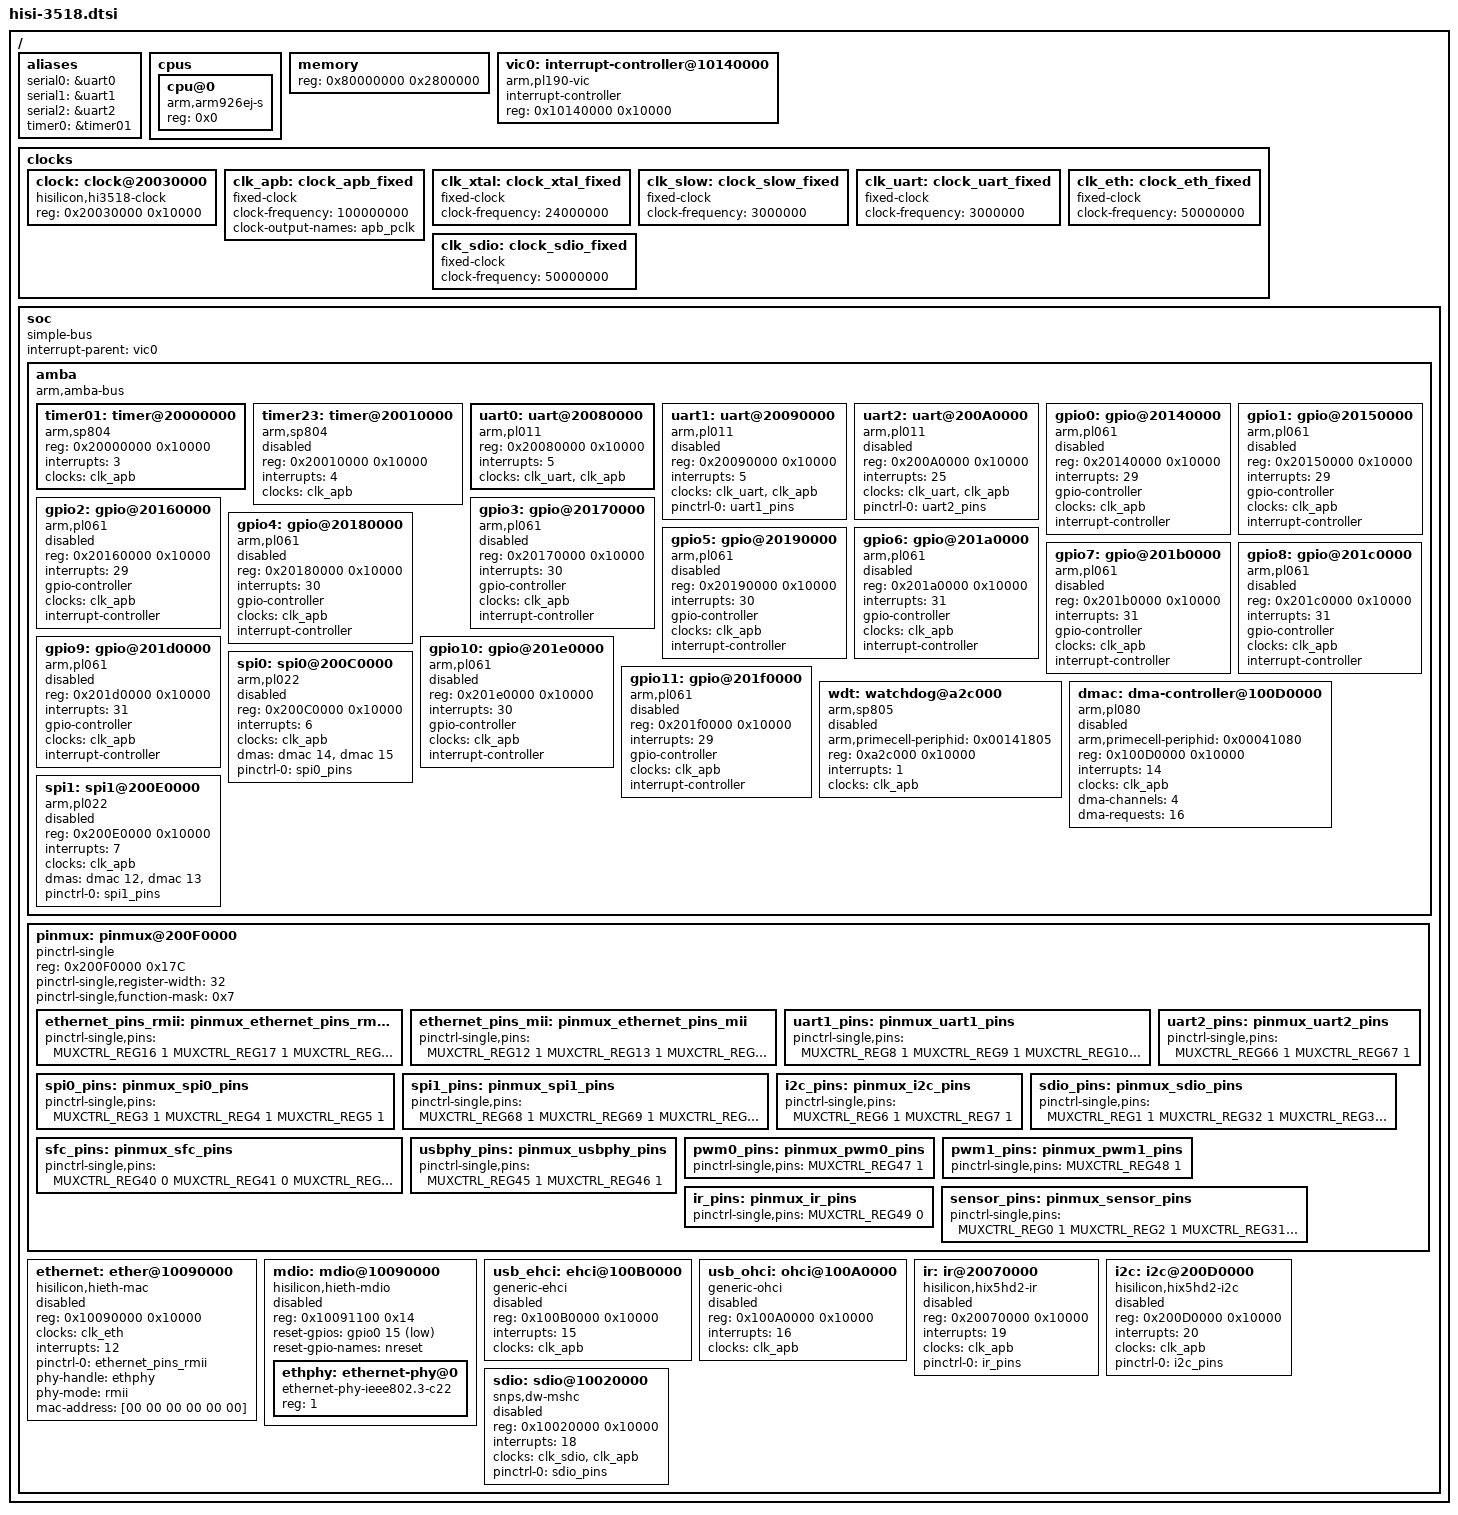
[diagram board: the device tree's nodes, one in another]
/*
 * Copyright (c) 2015 Robert Lukierski.
 * Copyright (c) 2013-2014 Linaro Ltd.
 * Copyright (c) 2013-2014 Hisilicon Limited.
 *
 * This program is free software; you can redistribute it and/or modify
 * it under the terms of the GNU General Public License version 2 as
 * publishhed by the Free Software Foundation.
 */

#include "skeleton.dtsi"
#include <dt-bindings/gpio/gpio.h>
#include <dt-bindings/input/input.h>
#include <dt-bindings/interrupt-controller/irq.h>
#include <dt-bindings/clock/hi3518-clock.h>

#define MUXCTRL_REG0 0x000
#define MUXCTRL_REG1 0x004
#define MUXCTRL_REG2 0x008
#define MUXCTRL_REG3 0x00C
#define MUXCTRL_REG4 0x010
#define MUXCTRL_REG5 0x014
#define MUXCTRL_REG6 0x018
#define MUXCTRL_REG7 0x01C
#define MUXCTRL_REG8 0x020
#define MUXCTRL_REG9 0x024
#define MUXCTRL_REG10 0x028
#define MUXCTRL_REG11 0x02C
#define MUXCTRL_REG12 0x030
#define MUXCTRL_REG13 0x034
#define MUXCTRL_REG14 0x038
#define MUXCTRL_REG15 0x03C
#define MUXCTRL_REG16 0x040
#define MUXCTRL_REG17 0x044
#define MUXCTRL_REG18 0x048
#define MUXCTRL_REG19 0x04C
#define MUXCTRL_REG20 0x050
#define MUXCTRL_REG21 0x054
#define MUXCTRL_REG22 0x058
#define MUXCTRL_REG23 0x05C
#define MUXCTRL_REG24 0x060
#define MUXCTRL_REG25 0x064
#define MUXCTRL_REG26 0x068
#define MUXCTRL_REG27 0x06C
#define MUXCTRL_REG28 0x070
#define MUXCTRL_REG29 0x074
#define MUXCTRL_REG30 0x078
#define MUXCTRL_REG31 0x07C
#define MUXCTRL_REG32 0x080
#define MUXCTRL_REG33 0x084
#define MUXCTRL_REG34 0x088
#define MUXCTRL_REG35 0x08C
#define MUXCTRL_REG36 0x090
#define MUXCTRL_REG37 0x094
#define MUXCTRL_REG38 0x098
#define MUXCTRL_REG39 0x09C
#define MUXCTRL_REG40 0x0A0
#define MUXCTRL_REG41 0x0A4
#define MUXCTRL_REG42 0x0A8
#define MUXCTRL_REG43 0x0AC
#define MUXCTRL_REG44 0x0B0
#define MUXCTRL_REG45 0x0B4
#define MUXCTRL_REG46 0x0B8
#define MUXCTRL_REG47 0x0BC
#define MUXCTRL_REG48 0x0C0
#define MUXCTRL_REG49 0x0C4
#define MUXCTRL_REG50 0x0C8
#define MUXCTRL_REG51 0x0CC
#define MUXCTRL_REG52 0x0D0
#define MUXCTRL_REG53 0x0D4
#define MUXCTRL_REG54 0x0D8
#define MUXCTRL_REG55 0x0DC
#define MUXCTRL_REG56 0x0E0
#define MUXCTRL_REG57 0x0E4
#define MUXCTRL_REG58 0x0E8
#define MUXCTRL_REG59 0x0EC
#define MUXCTRL_REG60 0x0F0
#define MUXCTRL_REG61 0x0F4
#define MUXCTRL_REG62 0x0F8
#define MUXCTRL_REG63 0x0FC
#define MUXCTRL_REG64 0x100
#define MUXCTRL_REG65 0x104
#define MUXCTRL_REG66 0x108
#define MUXCTRL_REG67 0x10C
#define MUXCTRL_REG68 0x110
#define MUXCTRL_REG69 0x114
#define MUXCTRL_REG70 0x118
#define MUXCTRL_REG71 0x11C
#define MUXCTRL_REG72 0x120
#define MUXCTRL_REG73 0x124
#define MUXCTRL_REG74 0x128
#define MUXCTRL_REG75 0x12C
#define MUXCTRL_REG76 0x130
#define MUXCTRL_REG77 0x134
#define MUXCTRL_REG78 0x138
#define MUXCTRL_REG79 0x13C
#define MUXCTRL_REG80 0x140
#define MUXCTRL_REG81 0x144
#define MUXCTRL_REG82 0x148
#define MUXCTRL_REG83 0x14C
#define MUXCTRL_REG84 0x150
#define MUXCTRL_REG85 0x154
#define MUXCTRL_REG86 0x158
#define MUXCTRL_REG87 0x15C
#define MUXCTRL_REG88 0x160
#define MUXCTRL_REG89 0x164
#define MUXCTRL_REG90 0x168
#define MUXCTRL_REG91 0x16C
#define MUXCTRL_REG92 0x170
#define MUXCTRL_REG93 0x174
#define MUXCTRL_REG94 0x178

/ {
    aliases {
        serial0 = &uart0;
        serial1 = &uart1;
        serial2 = &uart2;
        timer0 = &timer01;
    };
    
    cpus {
        #size-cells = <0>;
        #address-cells = <1>;
        
        cpu@0 {
            device_type = "cpu";
            compatible = "arm,arm926ej-s";
            reg = <0x0>;
        };
    };
    
    memory {
        device_type = "memory";
        reg = <0x80000000 0x2800000>; // 40 MB
    };
    
    vic0: interrupt-controller@10140000 {
        compatible = "arm,pl190-vic";
        interrupt-controller;
        #interrupt-cells = <1>;
        reg = <0x10140000 0x10000>;
        status = "okay";
    };
    
    clocks {
        #address-cells = <1>;
        #size-cells = <1>;
        ranges;
        
        clock: clock@20030000 {
            compatible = "hisilicon,hi3518-clock";
            reg = <0x20030000 0x10000>;
            #clock-cells = <1>;
        };
        
        clk_apb: clock_apb_fixed {
            compatible = "fixed-clock";
            #clock-cells = <0>;
            clock-frequency = <100000000>; 
            clock-output-names = "apb_pclk";
        };
        
        clk_xtal: clock_xtal_fixed {
            #clock-cells = <0>;
            compatible = "fixed-clock";
            clock-frequency = <24000000>;
        };
        
        clk_slow: clock_slow_fixed {
            #clock-cells = <0>;
            compatible = "fixed-clock";
            clock-frequency = <3000000>;
        };
        
        clk_uart: clock_uart_fixed {
            #clock-cells = <0>;
            compatible = "fixed-clock";
            clock-frequency = <3000000>;
        };
        
        clk_eth: clock_eth_fixed {
            #clock-cells = <0>;
            compatible = "fixed-clock";
            clock-frequency = <50000000>;
        };
        
        clk_sdio: clock_sdio_fixed {
            #clock-cells = <0>;
            compatible = "fixed-clock";
            clock-frequency = <50000000>;
        };
    };

    soc {
        device_type = "soc";
        #address-cells = <1>;
        #size-cells = <1>;
        compatible = "simple-bus";
        interrupt-parent = <&vic0>;
        ranges;

        amba {
            #address-cells = <1>;
            #size-cells = <1>;
            compatible = "arm,amba-bus";
            ranges;

            timer01: timer@20000000 {
                compatible = "arm,sp804", "arm,primecell";
                reg = <0x20000000 0x10000>;
                interrupts = <3>;
                clocks = <&clk_apb>;
                clock-names = "apb_pclk";
                status = "okay";
            };

            timer23: timer@20010000 {
                compatible = "arm,sp804", "arm,primecell";
                reg = <0x20010000 0x10000>;
                interrupts = <4>;
                clocks = <&clk_apb>;
                clock-names = "apb_pclk";
                status = "disabled";
            };
            
            uart0: uart@20080000 {
                compatible = "arm,pl011", "arm,primecell";
                reg = <0x20080000 0x10000>;
                interrupts = <5>;
                clocks = <&clk_uart>, <&clk_apb>;
                clock-names = "uartclk", "apb_pclk";
                status = "okay";
            };

            uart1: uart@20090000 {
                compatible = "arm,pl011", "arm,primecell";
                reg = <0x20090000 0x10000>;
                interrupts = <5>;
                clocks = <&clk_uart>, <&clk_apb>;
                clock-names = "uartclk", "apb_pclk";
                pinctrl-names = "default";
                pinctrl-0 = <&uart1_pins>;
                status = "disabled";
            };

            uart2: uart@200A0000 {
                compatible = "arm,pl011", "arm,primecell";
                reg = <0x200A0000 0x10000>;
                interrupts = <25>;
                clocks = <&clk_uart>, <&clk_apb>;
                clock-names = "uartclk", "apb_pclk";
                pinctrl-names = "default";
                pinctrl-0 = <&uart2_pins>;
                status = "disabled";
            };

            gpio0: gpio@20140000 {
                compatible = "arm,pl061", "arm,primecell";
                reg = <0x20140000 0x10000>;
                interrupts = <29>;
                gpio-controller;
                #gpio-cells = <2>;
                clocks = <&clk_apb>;
                clock-names = "apb_pclk";
                interrupt-controller;
                #interrupt-cells = <2>;
                status = "disabled";
            };

            gpio1: gpio@20150000 {
                compatible = "arm,pl061", "arm,primecell";
                reg = <0x20150000 0x10000>;
                interrupts = <29>;
                gpio-controller;
                #gpio-cells = <2>;
                clocks = <&clk_apb>;
                clock-names = "apb_pclk";
                interrupt-controller;
                #interrupt-cells = <2>;
                status = "disabled";
            };

            gpio2: gpio@20160000 {
                compatible = "arm,pl061", "arm,primecell";
                reg = <0x20160000 0x10000>;
                interrupts = <29>;
                gpio-controller;
                #gpio-cells = <2>;
                clocks = <&clk_apb>;
                clock-names = "apb_pclk";
                interrupt-controller;
                #interrupt-cells = <2>;
                status = "disabled";
            };

            gpio3: gpio@20170000 {
                compatible = "arm,pl061", "arm,primecell";
                reg = <0x20170000 0x10000>;
                interrupts = <30>;
                gpio-controller;
                #gpio-cells = <2>;
                clocks = <&clk_apb>;
                clock-names = "apb_pclk";
                interrupt-controller;
                #interrupt-cells = <2>;
                status = "disabled";
            };

            gpio4: gpio@20180000 {
                compatible = "arm,pl061", "arm,primecell";
                reg = <0x20180000 0x10000>;
                interrupts = <30>;
                gpio-controller;
                #gpio-cells = <2>;
                clocks = <&clk_apb>;
                clock-names = "apb_pclk";
                interrupt-controller;
                #interrupt-cells = <2>;
                status = "disabled";
            };

            gpio5: gpio@20190000 {
                compatible = "arm,pl061", "arm,primecell";
                reg = <0x20190000 0x10000>;
                interrupts = <30>;
                gpio-controller;
                #gpio-cells = <2>;
                clocks = <&clk_apb>;
                clock-names = "apb_pclk";
                interrupt-controller;
                #interrupt-cells = <2>;
                status = "disabled";
            };

            gpio6: gpio@201a0000 {
                compatible = "arm,pl061", "arm,primecell";
                reg = <0x201a0000 0x10000>;
                interrupts = <31>;
                gpio-controller;
                #gpio-cells = <2>;
                clocks = <&clk_apb>;
                clock-names = "apb_pclk";
                interrupt-controller;
                #interrupt-cells = <2>;
                status = "disabled";
            };

            gpio7: gpio@201b0000 {
                compatible = "arm,pl061", "arm,primecell";
                reg = <0x201b0000 0x10000>;
                interrupts = <31>;
                gpio-controller;
                #gpio-cells = <2>;
                clocks = <&clk_apb>;
                clock-names = "apb_pclk";
                interrupt-controller;
                #interrupt-cells = <2>;
                status = "disabled";
            };

            gpio8: gpio@201c0000 {
                compatible = "arm,pl061", "arm,primecell";
                reg = <0x201c0000 0x10000>;
                interrupts = <31>;
                gpio-controller;
                #gpio-cells = <2>;
                clocks = <&clk_apb>;
                clock-names = "apb_pclk";
                interrupt-controller;
                #interrupt-cells = <2>;
                status = "disabled";
            };

            gpio9: gpio@201d0000 {
                compatible = "arm,pl061", "arm,primecell";
                reg = <0x201d0000 0x10000>;
                interrupts = <31>;
                gpio-controller;
                #gpio-cells = <2>;
                clocks = <&clk_apb>;
                clock-names = "apb_pclk";
                interrupt-controller;
                #interrupt-cells = <2>;
                status = "disabled";
            };

            gpio10: gpio@201e0000 {
                compatible = "arm,pl061", "arm,primecell";
                reg = <0x201e0000 0x10000>;
                interrupts = <30>;
                gpio-controller;
                #gpio-cells = <2>;
                clocks = <&clk_apb>;
                clock-names = "apb_pclk";
                interrupt-controller;
                #interrupt-cells = <2>;
                status = "disabled";
            };

            gpio11: gpio@201f0000 {
                compatible = "arm,pl061", "arm,primecell";
                reg = <0x201f0000 0x10000>;
                interrupts = <29>;
                gpio-controller;
                #gpio-cells = <2>;
                clocks = <&clk_apb>;
                clock-names = "apb_pclk";
                interrupt-controller;
                #interrupt-cells = <2>;
                status = "disabled";
            };

            wdt: watchdog@a2c000 {
                compatible = "arm,sp805", "arm,primecell";
                arm,primecell-periphid = <0x00141805>;
                reg = <0xa2c000 0x10000>;
                interrupts = <1>;
                clocks = <&clk_apb>;
                clock-names = "apb_pclk";
                status = "disabled";
            };

            dmac: dma-controller@100D0000 {
                compatible = "arm,pl080", "arm,primecell";
                arm,primecell-periphid = <0x00041080>;
                reg = <0x100D0000 0x10000>;
                interrupts = <14>;
                clocks = <&clk_apb>;
                clock-names = "apb_pclk";
                #dma-cells = <1>;
                dma-channels = <4>;
                dma-requests = <16>;
                status = "disabled";
            };
            
            spi0: spi0@200C0000 {
                compatible = "arm,pl022", "arm,primecell";
                reg = <0x200C0000 0x10000>;
                #address-cells = <1>;
                #size-cells = <0>;
                interrupts = <6>;
                clocks = <&clk_apb>;
                clock-names = "apb_pclk";
                dmas = <&dmac 14>, <&dmac 15>;
                dma-names = "rx", "tx";
                pinctrl-names = "default";
                pinctrl-0 = <&spi0_pins>;
                status = "disabled";
            };
            
            spi1: spi1@200E0000 {
                compatible = "arm,pl022", "arm,primecell";
                reg = <0x200E0000 0x10000>;
                #address-cells = <1>;
                #size-cells = <0>;
                interrupts = <7>;
                clocks = <&clk_apb>;
                clock-names = "apb_pclk";
                dmas = <&dmac 12>, <&dmac 13>;
                dma-names = "rx", "tx";
                pinctrl-names = "default";
                pinctrl-0 = <&spi1_pins>;
                status = "disabled";
            };
        };

        /*
        sysctrl: system-controller@20050000 {
            compatible = "hisilicon,sysctrl", "syscon";
            reg = <0x20050000 0x10000>;
            
            #address-cells = <1>;
            #size-cells = <1>;
        };
        
        
        pio: pinctrl@200F0000 {
            compatible = "hisilicon,hi3518-pinctrl";
            reg = <0x200F0000 0x10000>, <0x20050000 0x10000>;
            clocks = <&clk_apb>;
            
            gpio-controller;
            interrupt-controller;
            #interrupt-cells = <2>;
            #size-cells = <0>;
            #gpio-cells = <3>;
        };
        */
        pinmux: pinmux@200F0000 {
            compatible = "pinctrl-single";
            reg = <0x200F0000 0x17C>;
            #address-cells = <1>;
            #size-cells = <1>;
            /* ranges; */
            
            pinctrl-single,register-width = <32>;
            pinctrl-single,function-mask = <0x7>;
            
            status = "okay";
#if 0      
            /* pin base, nr pins & gpio function */
            pinctrl-single,gpio-range = <
                    &range 0  36 0x00 
                    &range 37 1  0x02 /* SDIO_CDATA1 */
                    &range 38 2  0x00
                    &range 40 5  0x01 /* SFC */
                    &range 45 4  0x00
                    &range 49 1  0x01 /* IR_IN */
                    &range 50 16 0x01 /* NFC */
                    &range 66 11 0x00
                    &range 77 1  0x01 /* SVB_PWM */
                    &range 78 1  0x00
                    &range 79 16 0x01 /* SYS_RSTN_OUT + VIU */>;
            
            range: gpio-range {
                #pinctrl-single,gpio-range-cells = <3>;
            };
#endif
            ethernet_pins_rmii: pinmux_ethernet_pins_rmii  {
                pinctrl-single,pins = <MUXCTRL_REG16 1 /* MII_RXD1 */ 
                                       MUXCTRL_REG17 1 /* MII_RXD0 */ 
                                       MUXCTRL_REG20 1 /* MII_TXD1 */ 
                                       MUXCTRL_REG21 1 /* MII_TXD0 */ 
                                       MUXCTRL_REG23 3 /* RMII_CLK */ 
                                       MUXCTRL_REG24 1 /* MII_RXDV */ 
                                       MUXCTRL_REG25 1 /* MII_TXEN */ 
                                       MUXCTRL_REG26 1 /* MII_TXER */ 
                                       MUXCTRL_REG27 1 /* MII_RXER */ 
                                       MUXCTRL_REG29 1 /* MDCK */
                                       MUXCTRL_REG30 1 /* MDIO */>;
            };
            
            ethernet_pins_mii: pinmux_ethernet_pins_mii  {
                pinctrl-single,pins = <MUXCTRL_REG12 1 /* MII_CRS */ 
                                       MUXCTRL_REG13 1 /* MII_COL */ 
                                       MUXCTRL_REG14 1 /* MII_RXD3 */ 
                                       MUXCTRL_REG15 1 /* MII_RXD2 */                
                                       MUXCTRL_REG16 1 /* MII_RXD1 */ 
                                       MUXCTRL_REG17 1 /* MII_RXD0 */
                                       MUXCTRL_REG18 1 /* MII_TXD3 */ 
                                       MUXCTRL_REG19 1 /* MII_TXD2 */  
                                       MUXCTRL_REG20 1 /* MII_TXD1 */ 
                                       MUXCTRL_REG21 1 /* MII_TXD0 */
                                       MUXCTRL_REG22 1 /* MII_RXCK */ 
                                       MUXCTRL_REG23 3 /* RMII_CLK */ 
                                       MUXCTRL_REG24 1 /* MII_RXDV */ 
                                       MUXCTRL_REG25 1 /* MII_TXEN */ 
                                       MUXCTRL_REG26 1 /* MII_TXER */ 
                                       MUXCTRL_REG27 1 /* MII_RXER */ 
                                       MUXCTRL_REG28 1 /* EPHY_CLK */
                                       MUXCTRL_REG29 1 /* MDCK */
                                       MUXCTRL_REG30 1 /* MDIO */>;
            };
            
            uart1_pins: pinmux_uart1_pins {
                pinctrl-single,pins = <MUXCTRL_REG8 1 /* UART1_RTSN */ 
                                       MUXCTRL_REG9 1 /* UART1_RXD */ 
                                       MUXCTRL_REG10 1 /* UART1_CTSN */ 
                                       MUXCTRL_REG11 1 /* UART1_TXD */>;
            };
            
            uart2_pins: pinmux_uart2_pins {
                pinctrl-single,pins = <MUXCTRL_REG66 1 /* UART2_RXD */ 
                                       MUXCTRL_REG67 1 /* UART2_TXD */>;
            };
            
            spi0_pins: pinmux_spi0_pins {
                pinctrl-single,pins = <MUXCTRL_REG3 1 /* SPI0_SCLK */ 
                                       MUXCTRL_REG4 1 /* SPI0_SDO */ 
                                       MUXCTRL_REG5 1 /* SPI0_SDI */>;
            };
            
            spi1_pins: pinmux_spi1_pins {
                pinctrl-single,pins = <MUXCTRL_REG68 1 /* SPI1_SCLK */ 
                                       MUXCTRL_REG69 1 /* SPI1_SDO */ 
                                       MUXCTRL_REG70 1 /* SPI1_SDI */ 
                                       MUXCTRL_REG71 1 /* SPI1_CSN */>;
            };
            
            i2c_pins: pinmux_i2c_pins {
                pinctrl-single,pins = <MUXCTRL_REG6 1 /* I2C_SDA */ 
                                       MUXCTRL_REG7 1 /* I2C_SCL */>;
            };
            
            sdio_pins: pinmux_sdio_pins {
                pinctrl-single,pins = <MUXCTRL_REG1 1 /* SDIO_CCLK_OUT */ 
                                       MUXCTRL_REG32 1 /* SDIO_CARD_DETECT */ 
                                       MUXCTRL_REG33 1 /* SDIO_CARD_POWER_EN */ 
                                       MUXCTRL_REG34 1 /* SDIO_CWPR */ 
                                       MUXCTRL_REG35 1 /* SDIO_CCMD */ 
                                       MUXCTRL_REG36 1 /* SDIO_CDATA0 */ 
                                       MUXCTRL_REG37 1 /* SDIO_CDATA1 */ 
                                       MUXCTRL_REG38 1 /* SDIO_CDATA2 */ 
                                       MUXCTRL_REG39 1 /* SDIO_CDATA3 */>;
            };
            
            sfc_pins: pinmux_sfc_pins {
                pinctrl-single,pins = <MUXCTRL_REG40 0 /* SFC_DIO */ 
                                       MUXCTRL_REG41 0 /* SFC_WP_IO2 */ 
                                       MUXCTRL_REG42 0 /* SFC_CLK */ 
                                       MUXCTRL_REG43 0 /* SFC_DOI */
                                       MUXCTRL_REG44 0 /* SFC_HOLD_IO3 */>;
            };
            
            usbphy_pins: pinmux_usbphy_pins {
                pinctrl-single,pins = <MUXCTRL_REG45 1 /* USB_OVRCUR */ 
                                       MUXCTRL_REG46 1 /* USB_PWREN */>;
            };
            
            pwm0_pins: pinmux_pwm0_pins {
                pinctrl-single,pins = <MUXCTRL_REG47 1 /* PWM_OUT0 */ >;
            };
            
            pwm1_pins: pinmux_pwm1_pins {
                pinctrl-single,pins = <MUXCTRL_REG48 1 /* PWM_OUT1 */ >;
            };
            
            ir_pins: pinmux_ir_pins {
                pinctrl-single,pins = <MUXCTRL_REG49 0 /* IR_IN */ >;
            };
            
            sensor_pins: pinmux_sensor_pins {
                pinctrl-single,pins = <MUXCTRL_REG0 1 /* SHUTTER_TRIG */ 
                                       MUXCTRL_REG2 1 /* SENSOR_CLK */ 
                                       MUXCTRL_REG31 1 /* FLASH_TRIG */ 
                                       MUXCTRL_REG80 0 /* VIU_CLK */ 
                                       MUXCTRL_REG81 0 /* VIU_VS */ 
                                       MUXCTRL_REG82 0 /* VIU_HS */ 
                                       MUXCTRL_REG83 0 /* VIU_DAT11 */ 
                                       MUXCTRL_REG84 0 /* VIU_DAT10 */ 
                                       MUXCTRL_REG85 0 /* VIU_DAT9 */ 
                                       MUXCTRL_REG86 0 /* VIU_DAT8 */ 
                                       MUXCTRL_REG87 0 /* VIU_DAT7 */ 
                                       MUXCTRL_REG88 0 /* VIU_DAT6 */ 
                                       MUXCTRL_REG89 0 /* VIU_DAT5 */ 
                                       MUXCTRL_REG90 0 /* VIU_DAT4 */ 
                                       MUXCTRL_REG91 0 /* VIU_DAT3 */ 
                                       MUXCTRL_REG92 0 /* VIU_DAT2 */ 
                                       MUXCTRL_REG93 0 /* VIU_DAT1 */ 
                                       MUXCTRL_REG94 0 /* VIU_DAT0 */>;
            };
        };
        
        ethernet: ether@10090000 {
            compatible = "hisilicon,hieth-mac";
            reg = <0x10090000 0x10000>;
            
            clocks = <&clk_eth>;
            
            interrupts = <12>;
            
            pinctrl-names = "default";
            pinctrl-0 = <&ethernet_pins_rmii>;
            
            phy-handle = <&ethphy>;
            phy-mode = "rmii";
            
            mac-address = [00 00 00 00 00 00];
            status = "disabled";
        };
        
        mdio: mdio@10090000 {
            compatible = "hisilicon,hieth-mdio";
            reg = <0x10091100 0x14>;
            #address-cells = <1>;
            #size-cells = <0>;
            status = "disabled";
            
            reset-gpios = <&gpio0 15 GPIO_ACTIVE_LOW>;
            reset-gpio-names = "nreset";
            
            ethphy: ethernet-phy@0 {
                compatible = "ethernet-phy-ieee802.3-c22";
                reg = <1>;
            };
        };

        usb_ehci: ehci@100B0000 {
            compatible = "generic-ehci";
            reg = <0x100B0000 0x10000>;
            interrupts = <15>;
            clocks = <&clk_apb>;
            status = "disabled";
        };
        
        usb_ohci: ohci@100A0000 {
            compatible = "generic-ohci";
            reg = <0x100A0000 0x10000>;
            interrupts = <16>;
            clocks = <&clk_apb>;
            status = "disabled";
        };
        
        ir: ir@20070000 {
            compatible = "hisilicon,hix5hd2-ir";
            reg = <0x20070000 0x10000>;
            interrupts = <19>;
            clocks = <&clk_apb>;
            pinctrl-names = "default";
            pinctrl-0 = <&ir_pins>;
            status = "disabled";
        };

        i2c: i2c@200D0000 {
            compatible = "hisilicon,hix5hd2-i2c";
            reg = <0x200D0000 0x10000>;
            interrupts = <20>;
            clocks = <&clk_apb>;
            clock-names = "apb_pclk";
            #address-cells = <1>;
            #size-cells = <0>;
            pinctrl-names = "default";
            pinctrl-0 = <&i2c_pins>;
            status = "disabled";
        };
        
        sdio: sdio@10020000 {
            compatible = "snps,dw-mshc";
            reg = <0x10020000 0x10000>;
            interrupts = <18>;
            clocks = <&clk_sdio>, <&clk_apb>;
            clock-names = "ciu", "biu";
            pinctrl-names = "default";
            pinctrl-0 = <&sdio_pins>;
            status = "disabled";
        };
        
        /*
         * Porting TODO:
         * HiRTC
         * HiSFC
         * 
         * System Controller
         * Clock Controller
         * Reset Controller (or just reboot)
         */
        
        /*
         * NOTE: PWM clocks also 3 MHz, timers, watchdog and uarts switchable?
         */
        
        /*
         * Missing DT support:
         * WDG - SP805
         * DMAC - PL08x
         * SPI - PL022
         * GPIO - PLO61
         * 
         * Maybe use: OF_DEV_AUXDATA
         */
    };
};
